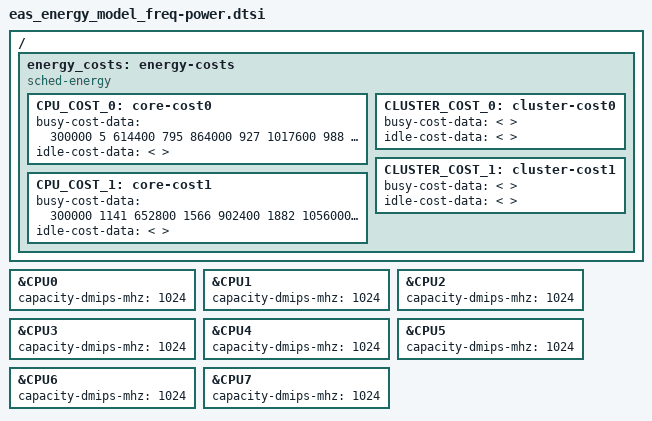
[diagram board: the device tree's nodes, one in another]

&CPU0 {
	capacity-dmips-mhz = <1024>;
};

&CPU1 {
	capacity-dmips-mhz = <1024>;
};

&CPU2 {
	capacity-dmips-mhz = <1024>;
};

&CPU3 {
	capacity-dmips-mhz = <1024>;
};

&CPU4 {
	capacity-dmips-mhz = <1024>;
};

&CPU5 {
	capacity-dmips-mhz = <1024>;
};

&CPU6 {
	capacity-dmips-mhz = <1024>;
};

&CPU7 {
	capacity-dmips-mhz = <1024>;
};

/ {
	energy_costs: energy-costs {
		compatible = "sched-energy";

		CPU_COST_0: core-cost0 {
			busy-cost-data = <
				 300000    5
				 614400  795
				 864000  927
				1017600  988
				1305600 1145
				1420800 1226
				1612800 1403
				1804800 1648
			>;
			idle-cost-data = <
				
			>;
		};

		CPU_COST_1: core-cost1 {
			busy-cost-data = <
				 300000 1141
				 652800 1566
				 902400 1882
				1056000 2064
				1401600 2511
				1536000 2687
				1804800 2994
				2016000 3391
			>;
			idle-cost-data = <
				
			>;
		};

		CLUSTER_COST_0: cluster-cost0 {
			busy-cost-data = <
			>;
			idle-cost-data = <
				
			>;
		};

		CLUSTER_COST_1: cluster-cost1 {
			busy-cost-data = <
			>;
			idle-cost-data = <
				
			>;
		};
	}; /* energy-costs */
};
